# STM32F479 register map
File version: 1.9
CPU: CM4 r0p1, little endian, MPU, FPU, 4 interrupt priority bits
Registers are 32-bit, read-write, reset 0x0 unless marked. A register's access mark holds for its fields unless they carry their own. Offsets are from the block's base; [hi:lo] are bit positions.

## I2C3 — Inter-integrated circuit
Base 0x40005C00
Same registers: I2C1 0x40005400, I2C2 0x40005800
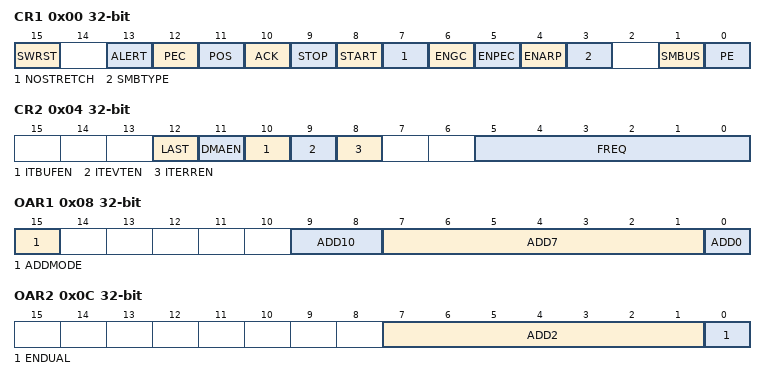
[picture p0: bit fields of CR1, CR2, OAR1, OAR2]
0x00 CR1 — Control register 1
  [15] SWRST — Software reset
  [13] ALERT — SMBus alert
  [12] PEC — Packet error checking
  [11] POS — Acknowledge/PEC Position (for data reception)
  [10] ACK — Acknowledge enable
  [9] STOP — Stop generation
  [8] START — Start generation
  [7] NOSTRETCH — Clock stretching disable (Slave mode)
  [6] ENGC — General call enable
  [5] ENPEC — PEC enable
  [4] ENARP — ARP enable
  [3] SMBTYPE — SMBus type
  [1] SMBUS — SMBus mode
  [0] PE — Peripheral enable
0x04 CR2 — Control register 2
  [12] LAST — DMA last transfer
  [11] DMAEN — DMA requests enable
  [10] ITBUFEN — Buffer interrupt enable
  [9] ITEVTEN — Event interrupt enable
  [8] ITERREN — Error interrupt enable
  [5:0] FREQ — Peripheral clock frequency
0x08 OAR1 — Own address register 1
  [15] ADDMODE — Addressing mode (slave mode)
  [9:8] ADD10 — Interface address
  [7:1] ADD7 — Interface address
  [0] ADD0 — Interface address
0x0C OAR2 — Own address register 2
  [7:1] ADD2 — Interface address
  [0] ENDUAL — Dual addressing mode enable
0x10 DR — Data register
  [7:0] DR — 8-bit data register
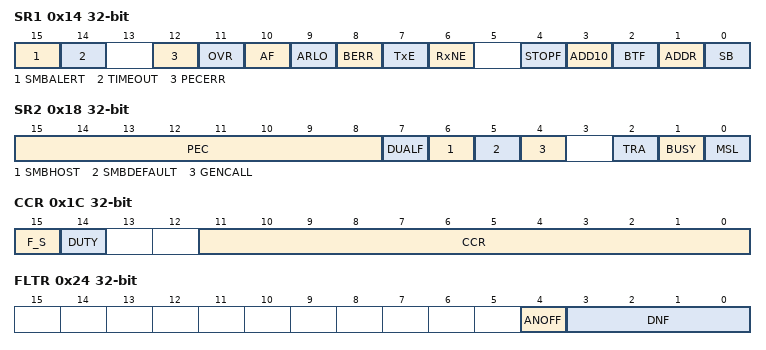
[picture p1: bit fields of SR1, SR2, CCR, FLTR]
0x14 SR1 access per field — Status register 1
  [15] SMBALERT rw — SMBus alert
  [14] TIMEOUT rw — Timeout or Tlow error
  [12] PECERR rw — PEC Error in reception
  [11] OVR rw — Overrun/Underrun
  [10] AF rw — Acknowledge failure
  [9] ARLO rw — Arbitration lost (master mode)
  [8] BERR rw — Bus error
  [7] TxE ro — Data register empty (transmitters)
  [6] RxNE ro — Data register not empty (receivers)
  [4] STOPF ro — Stop detection (slave mode)
  [3] ADD10 ro — 10-bit header sent (Master mode)
  [2] BTF ro — Byte transfer finished
  [1] ADDR ro — Address sent (master mode)/matched (slave mode)
  [0] SB ro — Start bit (Master mode)
0x18 SR2 ro — Status register 2
  [15:8] PEC — acket error checking register
  [7] DUALF — Dual flag (Slave mode)
  [6] SMBHOST — SMBus host header (Slave mode)
  [5] SMBDEFAULT — SMBus device default address (Slave mode)
  [4] GENCALL — General call address (Slave mode)
  [2] TRA — Transmitter/receiver
  [1] BUSY — Bus busy
  [0] MSL — Master/slave
0x1C CCR — Clock control register
  [15] F_S — I2C master mode selection
  [14] DUTY — Fast mode duty cycle
  [11:0] CCR — Clock control register in Fast/Standard mode (Master mode)
0x20 TRISE reset 0x2
  [5:0] TRISE — Maximum rise time in Fast/Standard mode (Master mode)
0x24 FLTR — I2C FLTR register
  [4] ANOFF — Analog noise filter OFF
  [3:0] DNF — Digital noise filter

## QUADSPI — QuadSPI interface
Base 0xA0001000
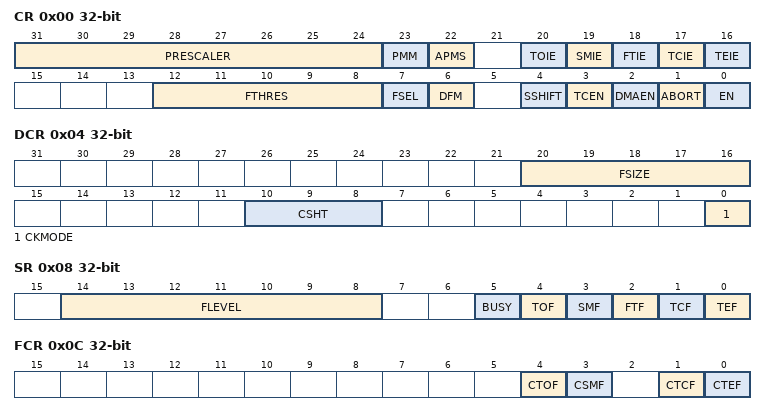
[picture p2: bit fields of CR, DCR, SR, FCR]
0x00 CR — control register
  [31:24] PRESCALER — Clock prescaler
  [23] PMM — Polling match mode
  [22] APMS — Automatic poll mode stop
  [20] TOIE — TimeOut interrupt enable
  [19] SMIE — Status match interrupt enable
  [18] FTIE — FIFO threshold interrupt enable
  [17] TCIE — Transfer complete interrupt enable
  [16] TEIE — Transfer error interrupt enable
  [12:8] FTHRES — IFO threshold level
  [7] FSEL — FLASH memory selection
  [6] DFM — Dual-flash mode
  [4] SSHIFT — Sample shift
  [3] TCEN — Timeout counter enable
  [2] DMAEN — DMA enable
  [1] ABORT — Abort request
  [0] EN — Enable
0x04 DCR — device configuration register
  [20:16] FSIZE — FLASH memory size
  [10:8] CSHT — Chip select high time
  [0] CKMODE — Mode 0 / mode 3
0x08 SR ro — status register
  [14:8] FLEVEL — FIFO level
  [5] BUSY
  [4] TOF — Timeout flag
  [3] SMF — Status match flag
  [2] FTF — FIFO threshold flag
  [1] TCF — Transfer complete flag
  [0] TEF — Transfer error flag
0x0C FCR — flag clear register
  [4] CTOF — Clear timeout flag
  [3] CSMF — Clear status match flag
  [1] CTCF — Clear transfer complete flag
  [0] CTEF — Clear transfer error flag
0x10 DLR — data length register
  [31:0] DL — Data length
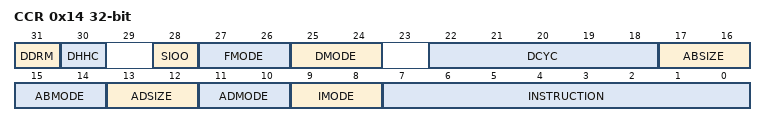
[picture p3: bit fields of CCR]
0x14 CCR — communication configuration register
  [31] DDRM — Double data rate mode
  [30] DHHC — DDR hold half cycle
  [28] SIOO — Send instruction only once mode
  [27:26] FMODE — Functional mode
  [25:24] DMODE — Data mode
  [22:18] DCYC — Number of dummy cycles
  [17:16] ABSIZE — Alternate bytes size
  [15:14] ABMODE — Alternate bytes mode
  [13:12] ADSIZE — Address size
  [11:10] ADMODE — Address mode
  [9:8] IMODE — Instruction mode
  [7:0] INSTRUCTION
0x18 AR — address register
  [31:0] ADDRESS
0x1C ABR
  [31:0] ALTERNATE
0x20 DR — data register
  [31:0] DATA
0x24 PSMKR — polling status mask register
  [31:0] MASK — Status mask
0x28 PSMAR — polling status match register
  [31:0] MATCH — Status match
0x2C PIR — polling interval register
  [15:0] INTERVAL — Polling interval
0x30 LPTR — low-power timeout register
  [15:0] TIMEOUT — Timeout period
